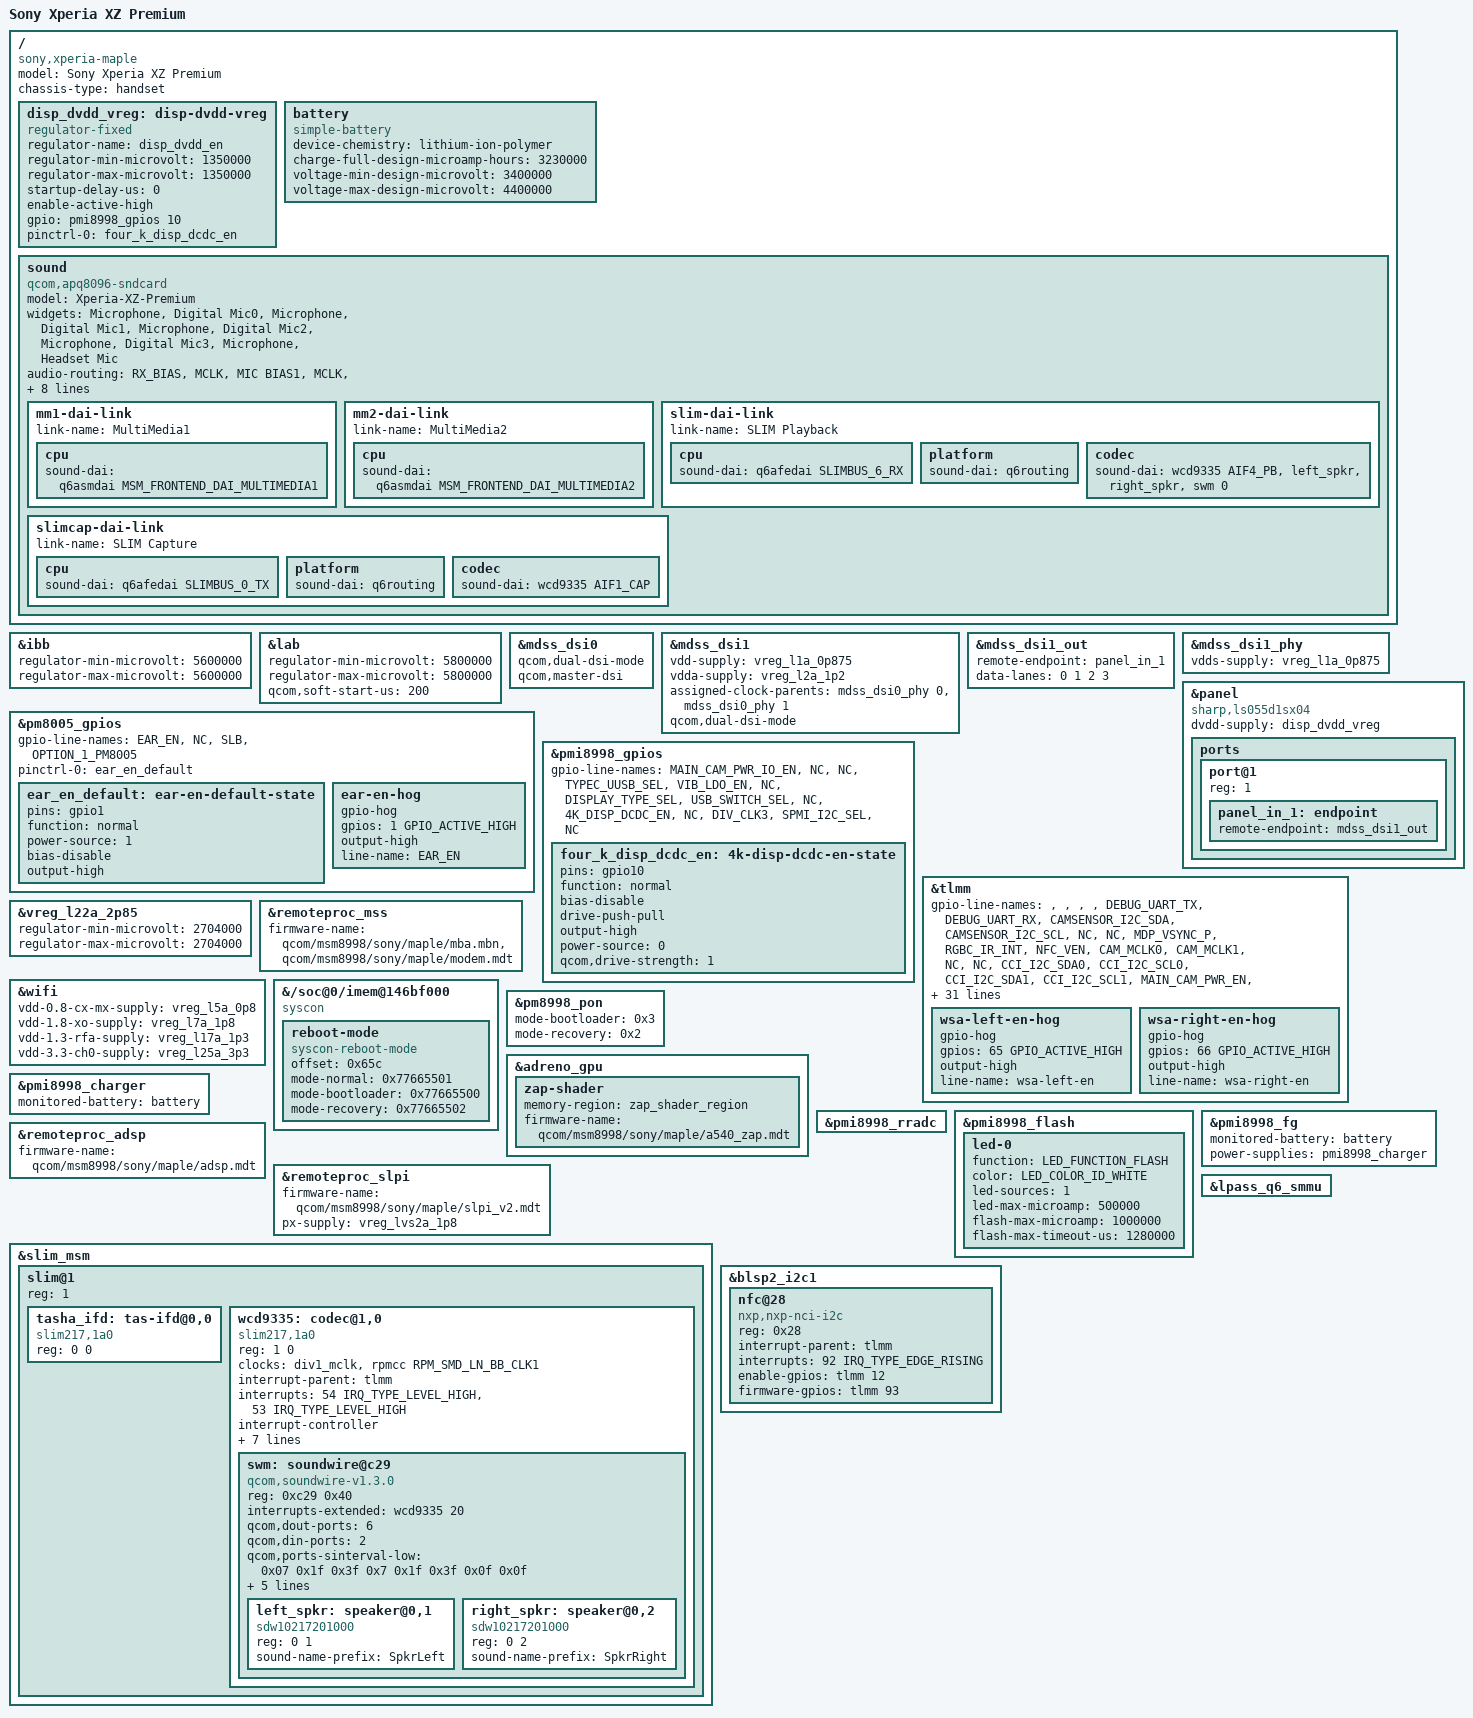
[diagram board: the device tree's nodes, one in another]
// SPDX-License-Identifier: BSD-3-Clause
/*
 * Copyright (c) 2021, AngeloGioacchino Del Regno
 *                     <angelogioacchino.delregno@somainline.org>
 */

/dts-v1/;

#include "msm8998-sony-xperia-yoshino.dtsi"
#include <dt-bindings/sound/qcom,wcd9335.h>

/ {
	model = "Sony Xperia XZ Premium";
	compatible = "sony,xperia-maple", "qcom,msm8998";
	chassis-type = "handset";

	disp_dvdd_vreg: disp-dvdd-vreg {
		compatible = "regulator-fixed";
		regulator-name = "disp_dvdd_en";
		regulator-min-microvolt = <1350000>;
		regulator-max-microvolt = <1350000>;
		startup-delay-us = <0>;
		enable-active-high;
		gpio = <&pmi8998_gpios 10 GPIO_ACTIVE_HIGH>;
		pinctrl-names = "default";
		pinctrl-0 = <&four_k_disp_dcdc_en>;
	};
};

&ibb {
	regulator-min-microvolt = <5600000>;
	regulator-max-microvolt = <5600000>;
};

&lab {
	regulator-min-microvolt = <5800000>;
	regulator-max-microvolt = <5800000>;
	qcom,soft-start-us = <200>;
};

&mdss_dsi0 {
	qcom,dual-dsi-mode;
	qcom,master-dsi;
};

&mdss_dsi1 {
	vdd-supply = <&vreg_l1a_0p875>;
	vdda-supply = <&vreg_l2a_1p2>;
	assigned-clock-parents = <&mdss_dsi0_phy 0>,
				 <&mdss_dsi0_phy 1>;
	qcom,dual-dsi-mode;
	status = "okay";
};

&mdss_dsi1_out {
	remote-endpoint = <&panel_in_1>;
	data-lanes = <0 1 2 3>;
};

&mdss_dsi1_phy {
	vdds-supply = <&vreg_l1a_0p875>;
	status = "okay";
};

&panel {
	compatible = "sharp,ls055d1sx04", "novatek,nt35950";

	dvdd-supply = <&disp_dvdd_vreg>;

	ports {
		port@1 {
			reg = <1>;

			panel_in_1: endpoint {
				remote-endpoint = <&mdss_dsi1_out>;
			};
		};
	};
};

&pm8005_gpios {
	gpio-line-names = "EAR_EN", /* GPIO_1 */
			  "NC",
			  "SLB",
			  "OPTION_1_PM8005";
};

&pmi8998_gpios {
	gpio-line-names = "MAIN_CAM_PWR_IO_EN", /* GPIO_1 */
			  "NC",
			  "NC",
			  "TYPEC_UUSB_SEL",
			  "VIB_LDO_EN",
			  "NC",
			  "DISPLAY_TYPE_SEL",
			  "USB_SWITCH_SEL",
			  "NC",
			  "4K_DISP_DCDC_EN", /* GPIO_10 */
			  "NC",
			  "DIV_CLK3",
			  "SPMI_I2C_SEL",
			  "NC";

	four_k_disp_dcdc_en: 4k-disp-dcdc-en-state {
		pins = "gpio10";
		function = "normal";
		bias-disable;
		drive-push-pull;
		output-high;
		power-source = <0>;
		qcom,drive-strength = <1>;
	};
};

&tlmm {

	gpio-line-names = "", /* GPIO_0 */
			  "",
			  "",
			  "",
			  "DEBUG_UART_TX",
			  "DEBUG_UART_RX",
			  "CAMSENSOR_I2C_SDA",
			  "CAMSENSOR_I2C_SCL",
			  "NC",
			  "NC",
			  "MDP_VSYNC_P", /* GPIO_10 */
			  "RGBC_IR_INT",
			  "NFC_VEN",
			  "CAM_MCLK0",
			  "CAM_MCLK1",
			  "NC",
			  "NC",
			  "CCI_I2C_SDA0",
			  "CCI_I2C_SCL0",
			  "CCI_I2C_SDA1",
			  "CCI_I2C_SCL1", /* GPIO_20 */
			  "MAIN_CAM_PWR_EN",
			  "TOF_INT_N",
			  "NC",
			  "NC",
			  "CHAT_CAM_PWR_EN",
			  "NC",
			  "TOF_RESET_N",
			  "CAM2_RSTN",
			  "NC",
			  "CAM1_RSTN", /* GPIO_30 */
			  "NC",
			  "NC",
			  "NC",
			  "NC",
			  "NC",
			  "NC",
			  "NC",
			  "CC_DIR",
			  "UIM2_DETECT_EN",
			  "FP_RESET_N", /* GPIO_40 */
			  "NC",
			  "NC",
			  "NC",
			  "NC",
			  "BT_HCI_UART_TXD",
			  "BT_HCI_UART_RXD",
			  "BT_HCI_UART_CTS_N",
			  "BT_HCI_UART_RFR_N",
			  "NC",
			  "NC", /* GPIO_50 */
			  "NC",
			  "NC",
			  "CODEC_INT2_N",
			  "CODEC_INT1_N",
			  "APPS_I2C_SDA",
			  "APPS_I2C_SCL",
			  "FORCED_USB_BOOT",
			  "NC",
			  "NC",
			  "NC", /* GPIO_60 */
			  "NC",
			  "NC",
			  "TRAY2_DET_DS",
			  "CODEC_RST_N",
			  "WSA_L_EN",
			  "WSA_R_EN",
			  "NC",
			  "NC",
			  "NC",
			  "LPASS_SLIMBUS_CLK", /* GPIO_70 */
			  "LPASS_SLIMBUS_DATA0",
			  "LPASS_SLIMBUS_DATA1",
			  "BT_FM_SLIMBUS_DATA",
			  "BT_FM_SLIMBUS_CLK",
			  "NC",
			  "RF_LCD_ID_EN",
			  "NC",
			  "NC",
			  "NC",
			  "NC", /* GPIO_80 */
			  "SW_SERVICE",
			  "TX_GTR_THRES_IN",
			  "HW_ID0",
			  "HW_ID1",
			  "NC",
			  "NC",
			  "TS_I2C_SDA",
			  "TS_I2C_SCL",
			  "TS_RESET_N",
			  "NC", /* GPIO_90 */
			  "NC",
			  "NFC_IRQ",
			  "NFC_DWLD_EN",
			  "DISP_RESET_N",
			  "TRAY2_DET",
			  "CAM_SOF",
			  "RFFE6_CLK",
			  "RFFE6_DATA",
			  "DEBUG_GPIO0",
			  "DEBUG_GPIO1", /* GPIO_100 */
			  "GRFC4",
			  "NC",
			  "NC",
			  "RSVD",
			  "UIM2_DATA",
			  "UIM2_CLK",
			  "UIM2_RESET",
			  "UIM2_PRESENT",
			  "UIM1_DATA",
			  "UIM1_CLK", /* GPIO_110 */
			  "UIM1_RST",
			  "UIM1_PRESENT",
			  "UIM_BATT_ALARM",
			  "RSVD",
			  "NC",
			  "NC",
			  "ACCEL_INT",
			  "GYRO_INT",
			  "COMPASS_INT",
			  "ALS_PROX_INT_N", /* GPIO_120 */
			  "FP_INT_N",
			  "NC",
			  "BAROMETER_INT",
			  "ACC_COVER_OPEN",
			  "TS_INT_N",
			  "NC",
			  "NC",
			  "USB_DETECT_EN",
			  "NC",
			  "QLINK_REQUEST", /* GPIO_130 */
			  "QLINK_ENABLE",
			  "NC",
			  "TS_VDDIO_EN",
			  "WMSS_RESET_N",
			  "PA_INDICATOR_OR",
			  "NC",
			  "RFFE3_DATA",
			  "RFFE3_CLK",
			  "RFFE4_DATA",
			  "RFFE4_CLK", /* GPIO_140 */
			  "RFFE5_DATA",
			  "RFFE5_CLK",
			  "GNSS_EN",
			  "MSS_LTE_COXM_TXD",
			  "MSS_LTE_COXM_RXD",
			  "RFFE2_DATA",
			  "RFFE2_CLK",
			  "RFFE1_DATA",
			  "RFFE1_CLK";
};

&vreg_l22a_2p85 {
	regulator-min-microvolt = <2704000>;
	regulator-max-microvolt = <2704000>;
};

&remoteproc_mss {
	firmware-name = "qcom/msm8998/sony/maple/mba.mbn",
			"qcom/msm8998/sony/maple/modem.mdt";
	status = "okay";
};

&wifi {
	vdd-0.8-cx-mx-supply = <&vreg_l5a_0p8>;
	vdd-1.8-xo-supply = <&vreg_l7a_1p8>;
	vdd-1.3-rfa-supply = <&vreg_l17a_1p3>;
	vdd-3.3-ch0-supply = <&vreg_l25a_3p3>;
	status = "okay";
};

/* Sony XBoot reads the restart reason from IMEM (like downstream "restart_reason@65c") */
&{/soc@0/imem@146bf000} {
	compatible = "syscon", "simple-mfd";

	reboot-mode {
		compatible = "syscon-reboot-mode";
		offset = <0x65c>;
		mode-normal = <0x77665501>;
		mode-bootloader = <0x77665500>;
		mode-recovery = <0x77665502>;
	};
};

/*
 * Sony XBoot uses its own PMIC restart reason numbering (downstream
 * enum pon_restart_reason: recovery = 2, bootloader = 3).
 */
&pm8998_pon {
	mode-bootloader = <0x3>;
	mode-recovery = <0x2>;
};

&adreno_gpu {
	status = "okay";

	zap-shader {
		memory-region = <&zap_shader_region>;
		firmware-name = "qcom/msm8998/sony/maple/a540_zap.mdt";
	};
};

/ {
	battery: battery {
		compatible = "simple-battery";
		device-chemistry = "lithium-ion-polymer";
		charge-full-design-microamp-hours = <3230000>;
		voltage-min-design-microvolt = <3400000>;
		voltage-max-design-microvolt = <4400000>;
	};
};

&pmi8998_charger {
	monitored-battery = <&battery>;
	status = "okay";
};

&pmi8998_rradc {
	status = "okay";
};

&pmi8998_flash {
	status = "okay";

	led-0 {
		function = LED_FUNCTION_FLASH;
		color = <LED_COLOR_ID_WHITE>;
		led-sources = <1>;
		led-max-microamp = <500000>;
		flash-max-microamp = <1000000>;
		flash-max-timeout-us = <1280000>;
	};
};

&pmi8998_fg {
	monitored-battery = <&battery>;
	power-supplies = <&pmi8998_charger>;
	status = "okay";
};

&remoteproc_adsp {
	firmware-name = "qcom/msm8998/sony/maple/adsp.mdt";
	status = "okay";
};

&remoteproc_slpi {
	firmware-name = "qcom/msm8998/sony/maple/slpi_v2.mdt";
	px-supply = <&vreg_lvs2a_1p8>;
	status = "okay";
};

/ {
	sound {
		compatible = "qcom,apq8096-sndcard";
		model = "Xperia-XZ-Premium";
		widgets = "Microphone", "Digital Mic0",
			  "Microphone", "Digital Mic1",
			  "Microphone", "Digital Mic2",
			  "Microphone", "Digital Mic3",
			  "Microphone", "Headset Mic";
		audio-routing = "RX_BIAS", "MCLK",
				"MIC BIAS1", "MCLK",
				"MIC BIAS2", "MCLK",
				"MIC BIAS3", "MCLK",
				"MIC BIAS4", "MCLK",
				"DMIC0", "Digital Mic0",
				"DMIC1", "Digital Mic1",
				"DMIC2", "Digital Mic2",
				"DMIC3", "Digital Mic3",
				"AMIC2", "Headset Mic",
				"DMIC0", "MIC BIAS1",
				"DMIC1", "MIC BIAS1",
				"DMIC2", "MIC BIAS3",
				"DMIC3", "MIC BIAS4",
				"AMIC2", "MIC BIAS2",
				"SpkrLeft IN", "SPK1 OUT",
				"SpkrRight IN", "SPK2 OUT";

		mm1-dai-link {
			link-name = "MultiMedia1";

			cpu {
				sound-dai = <&q6asmdai MSM_FRONTEND_DAI_MULTIMEDIA1>;
			};
		};

		mm2-dai-link {
			link-name = "MultiMedia2";

			cpu {
				sound-dai = <&q6asmdai MSM_FRONTEND_DAI_MULTIMEDIA2>;
			};
		};

		slim-dai-link {
			link-name = "SLIM Playback";

			cpu {
				sound-dai = <&q6afedai SLIMBUS_6_RX>;
			};

			platform {
				sound-dai = <&q6routing>;
			};

			codec {
				sound-dai = <&wcd9335 AIF4_PB>, <&left_spkr>,
					    <&right_spkr>, <&swm 0>;
			};
		};

		slimcap-dai-link {
			link-name = "SLIM Capture";

			cpu {
				sound-dai = <&q6afedai SLIMBUS_0_TX>;
			};

			platform {
				sound-dai = <&q6routing>;
			};

			codec {
				sound-dai = <&wcd9335 AIF1_CAP>;
			};
		};
	};
};

&slim_msm {
	status = "okay";

	slim@1 {
		reg = <1>;
		#address-cells = <2>;
		#size-cells = <0>;

		tasha_ifd: tas-ifd@0,0 {
			compatible = "slim217,1a0";
			reg = <0 0>;
		};

		wcd9335: codec@1,0 {
			compatible = "slim217,1a0";
			reg = <1 0>;

			clock-names = "mclk", "slimbus";
			clocks = <&div1_mclk>,
				 <&rpmcc RPM_SMD_LN_BB_CLK1>;
			interrupt-parent = <&tlmm>;
			interrupts = <54 IRQ_TYPE_LEVEL_HIGH>,
				     <53 IRQ_TYPE_LEVEL_HIGH>;
			interrupt-names = "intr1", "intr2";
			interrupt-controller;
			#interrupt-cells = <1>;

			reset-gpios = <&tlmm 64 GPIO_ACTIVE_LOW>;
			slim-ifc-dev = <&tasha_ifd>;

			#sound-dai-cells = <1>;

			vdd-buck-supply = <&vreg_s4a_1p8>;
			vdd-buck-sido-supply = <&vreg_s4a_1p8>;
			vdd-tx-supply = <&vreg_s4a_1p8>;
			vdd-rx-supply = <&vreg_s4a_1p8>;
			vdd-io-supply = <&vreg_s4a_1p8>;

			#clock-cells = <0>;
			#address-cells = <1>;
			#size-cells = <1>;

			swm: soundwire@c29 {
				compatible = "qcom,soundwire-v1.3.0";
				reg = <0xc29 0x40>;
				interrupts-extended = <&wcd9335 20>;

				qcom,dout-ports = <6>;
				qcom,din-ports = <2>;
				qcom,ports-sinterval-low = /bits/ 8 <0x07 0x1f 0x3f 0x7 0x1f 0x3f 0x0f 0x0f>;
				qcom,ports-offset1 = /bits/ 8 <0x01 0x02 0x0c 0x6 0x12 0x0d 0x07 0x0a>;
				qcom,ports-offset2 = /bits/ 8 <0x00 0x00 0x1f 0x00 0x00 0x1f 0x00 0x00>;

				#sound-dai-cells = <1>;
				clocks = <&wcd9335>;
				clock-names = "iface";
				#address-cells = <2>;
				#size-cells = <0>;

				left_spkr: speaker@0,1 {
					compatible = "sdw10217201000";
					reg = <0 1>;
					#thermal-sensor-cells = <0>;
					sound-name-prefix = "SpkrLeft";
					#sound-dai-cells = <0>;
				};

				right_spkr: speaker@0,2 {
					compatible = "sdw10217201000";
					reg = <0 2>;
					#thermal-sensor-cells = <0>;
					sound-name-prefix = "SpkrRight";
					#sound-dai-cells = <0>;
				};
			};
		};
	};
};

&blsp2_i2c1 {
	status = "okay";

	nfc@28 {
		compatible = "nxp,nxp-nci-i2c";
		reg = <0x28>;

		interrupt-parent = <&tlmm>;
		interrupts = <92 IRQ_TYPE_EDGE_RISING>;

		enable-gpios = <&tlmm 12 GPIO_ACTIVE_HIGH>;
		firmware-gpios = <&tlmm 93 GPIO_ACTIVE_HIGH>;
	};
};

/* Needed by the ADSP to reach the shared audio buffers */
&lpass_q6_smmu {
	status = "okay";
};

/* Earpiece amplifier enable */
&pm8005_gpios {
	pinctrl-names = "default";
	pinctrl-0 = <&ear_en_default>;

	/* 1.8 V push-pull, as the vendor kernel configures it */
	ear_en_default: ear-en-default-state {
		pins = "gpio1";
		function = "normal";
		power-source = <1>;
		bias-disable;
		output-high;
	};

	ear-en-hog {
		gpio-hog;
		gpios = <1 GPIO_ACTIVE_HIGH>;
		output-high;
		line-name = "EAR_EN";
	};
};

&tlmm {
	/*
	 * Keep the WSA881x amplifiers out of shutdown: power cycling them on
	 * every runtime suspend makes re-enumeration on the WCD9335 SoundWire
	 * master unreliable.
	 */
	wsa-left-en-hog {
		gpio-hog;
		gpios = <65 GPIO_ACTIVE_HIGH>;
		output-high;
		line-name = "wsa-left-en";
	};

	wsa-right-en-hog {
		gpio-hog;
		gpios = <66 GPIO_ACTIVE_HIGH>;
		output-high;
		line-name = "wsa-right-en";
	};
};
